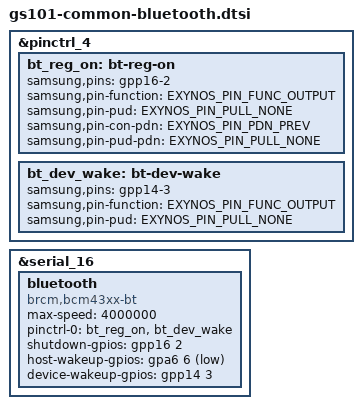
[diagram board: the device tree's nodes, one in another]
// SPDX-License-Identifier: GPL-2.0-only
/*
 * Common Bluetooth device tree for gs101 boards.
 *
 * Copyright 2019 Google LLC
 *
 */

#include <dt-bindings/gpio/gpio.h>
#include <dt-bindings/pinctrl/samsung.h>

&pinctrl_4 {
	bt_reg_on: bt-reg-on {
		samsung,pins ="gpp16-2";
		samsung,pin-function = <EXYNOS_PIN_FUNC_OUTPUT>;
		samsung,pin-pud = <EXYNOS_PIN_PULL_NONE>;
		samsung,pin-con-pdn = <EXYNOS_PIN_PDN_PREV>;
		samsung,pin-pud-pdn = <EXYNOS_PIN_PULL_NONE>;
	};
	bt_dev_wake: bt-dev-wake {
		samsung,pins ="gpp14-3";
		samsung,pin-function = <EXYNOS_PIN_FUNC_OUTPUT>;
		samsung,pin-pud = <EXYNOS_PIN_PULL_NONE>;
	};
};

&serial_16 {
	status = "okay";

	bluetooth {
		compatible = "brcm,bcm43xx-bt";
		max-speed = <4000000>;
		pinctrl-0 = <&bt_reg_on &bt_dev_wake>;
		pinctrl-names = "default";
		shutdown-gpios = <&gpp16 2 GPIO_ACTIVE_HIGH>;
		host-wakeup-gpios = <&gpa6 6 0xf>;
		device-wakeup-gpios = <&gpp14 3 GPIO_ACTIVE_HIGH>;
		status = "okay";
	};
};
